# CM_PER register map
Vendor: Texas Instruments
Peripheral module from a debugger description file (folder am335x).
Registers are 32-bit, access per field, no defined reset value unless marked. A register's access mark holds for its fields unless they carry their own. Offsets are as the file gives them; lines under a group give offsets from that group; [hi:lo] are bit positions; {n}, {i} and the like mark numbered series; 'fields as' and 'values as' point back to an identical list; <NAME> marks a mode.

## CM_PER
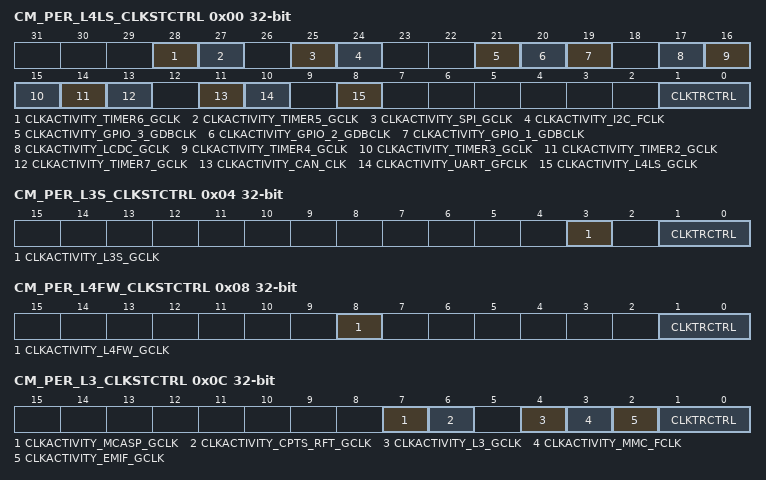
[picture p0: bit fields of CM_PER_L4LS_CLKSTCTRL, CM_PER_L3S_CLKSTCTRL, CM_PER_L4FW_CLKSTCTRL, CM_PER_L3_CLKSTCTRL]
0x00 CM_PER_L4LS_CLKSTCTRL — This register enables the domain power state transition. It controls the SW supervised clock domain state transition between ON-PER and ON-INPER states. It also hold one status bit per clock input of the domain.
  [28] CLKACTIVITY_TIMER6_GCLK ro — This field indicates the state of the TIMER6 CLKTIMER clock in the domain.
    0=Inact (Corresponding clock is gated); 1=Act (Corresponding clock is active)
  [27] CLKACTIVITY_TIMER5_GCLK ro — This field indicates the state of the TIMER5 CLKTIMER clock in the domain.
    values as CLKACTIVITY_TIMER6_GCLK
  [25] CLKACTIVITY_SPI_GCLK ro — This field indicates the state of the SPI_GCLK clock in the domain.
    values as CLKACTIVITY_TIMER6_GCLK
  [24] CLKACTIVITY_I2C_FCLK ro — This field indicates the state of the I2C _FCLK clock in the domain.
    values as CLKACTIVITY_TIMER6_GCLK
  [21] CLKACTIVITY_GPIO_3_GDBCLK ro — This field indicates the state of the GPIO3_GDBCLK clock in the domain.
    values as CLKACTIVITY_TIMER6_GCLK
  [20] CLKACTIVITY_GPIO_2_GDBCLK ro — This field indicates the state of the GPIO2_ GDBCLK clock in the domain.
    values as CLKACTIVITY_TIMER6_GCLK
  [19] CLKACTIVITY_GPIO_1_GDBCLK ro — This field indicates the state of the GPIO1_GDBCLK clock in the domain.
    values as CLKACTIVITY_TIMER6_GCLK
  [17] CLKACTIVITY_LCDC_GCLK ro — This field indicates the state of the LCD clock in the domain.
    values as CLKACTIVITY_TIMER6_GCLK
  [16] CLKACTIVITY_TIMER4_GCLK ro — This field indicates the state of the TIMER4 CLKTIMER clock in the domain.
    values as CLKACTIVITY_TIMER6_GCLK
  [15] CLKACTIVITY_TIMER3_GCLK ro — This field indicates the state of the TIMER3 CLKTIMER clock in the domain.
    values as CLKACTIVITY_TIMER6_GCLK
  [14] CLKACTIVITY_TIMER2_GCLK ro — This field indicates the state of the TIMER2 CLKTIMER clock in the domain.
    values as CLKACTIVITY_TIMER6_GCLK
  [13] CLKACTIVITY_TIMER7_GCLK ro — This field indicates the state of the TIMER7 CLKTIMER clock in the domain.
    values as CLKACTIVITY_TIMER6_GCLK
  [11] CLKACTIVITY_CAN_CLK ro — This field indicates the state of the CAN_CLK clock in the domain.
    values as CLKACTIVITY_TIMER6_GCLK
  [10] CLKACTIVITY_UART_GFCLK ro — This field indicates the state of the UART_GFCLK clock in the domain.
    values as CLKACTIVITY_TIMER6_GCLK
  [8] CLKACTIVITY_L4LS_GCLK ro — This field indicates the state of the L4LS_GCLK clock in the domain.
    values as CLKACTIVITY_TIMER6_GCLK
  [1:0] CLKTRCTRL rw — Controls the clock state transition of the L4 SLOW clock domain in PER power domain.
    0=NO_SLEEP (NO_SLEEP: Sleep transition cannot be initiated. Wakeup transition may however occur.); 1=SW_SLEEP (SW_SLEEP: Start a software forced sleep transition on the domain.); 2=SW_WKUP (SW_WKUP: Start a software forced wake-up transition on the domain.)
0x04 CM_PER_L3S_CLKSTCTRL — This register enables the domain power state transition. It controls the SW supervised clock domain state transition between ON-ACTIVE and ON-INACTIVE states. It also hold one status bit per clock input of the domain.
  [3] CLKACTIVITY_L3S_GCLK ro — This field indicates the state of the L3S_GCLK clock in the domain.
    0=Inact; 1=Act
  [1:0] CLKTRCTRL rw — Controls the clock state transition of the L3 Slow clock domain.
    values as CM_PER_L4LS_CLKSTCTRL.CLKTRCTRL
0x08 CM_PER_L4FW_CLKSTCTRL — This register enables the domain power state transition. It controls the SW supervised clock domain state transition between ON-ACTIVE and ON-INACTIVE states. It also hold one status bit per clock input of the domain.
  [8] CLKACTIVITY_L4FW_GCLK ro — This field indicates the state of the L4FW clock in the domain.
    values as CM_PER_L4LS_CLKSTCTRL.CLKACTIVITY_TIMER6_GCLK
  [1:0] CLKTRCTRL rw — Controls the clock state transition of the L4 Firewall clock domain.
    values as CM_PER_L4LS_CLKSTCTRL.CLKTRCTRL
0x0C CM_PER_L3_CLKSTCTRL — This register enables the domain power state transition. It controls the SW supervised clock domain state transition between ON-ACTIVE and ON-INACTIVE states. It also hold one status bit per clock input of the domain.
  [7] CLKACTIVITY_MCASP_GCLK ro — This field indicates the state of the MCASP_GCLK clock in the domain.
    0=Inact; 1=Act
  [6] CLKACTIVITY_CPTS_RFT_GCLK ro — This field indicates the state of the CLKACTIVITY_CPTS_RFT_GCLK clock in the domain.
    0=Inact; 1=Act
  [4] CLKACTIVITY_L3_GCLK ro — This field indicates the state of the L3_GCLK clock in the domain.
    0=Inact; 1=Act
  [3] CLKACTIVITY_MMC_FCLK ro — This field indicates the state of the MMC_GCLK clock in the domain.
    0=Inact; 1=Act
  [2] CLKACTIVITY_EMIF_GCLK ro — This field indicates the state of the EMIF_GCLK clock in the domain.
    0=Inact; 1=Act
  [1:0] CLKTRCTRL rw — Controls the clock state transition of the L3 clock domain.
    values as CM_PER_L4LS_CLKSTCTRL.CLKTRCTRL
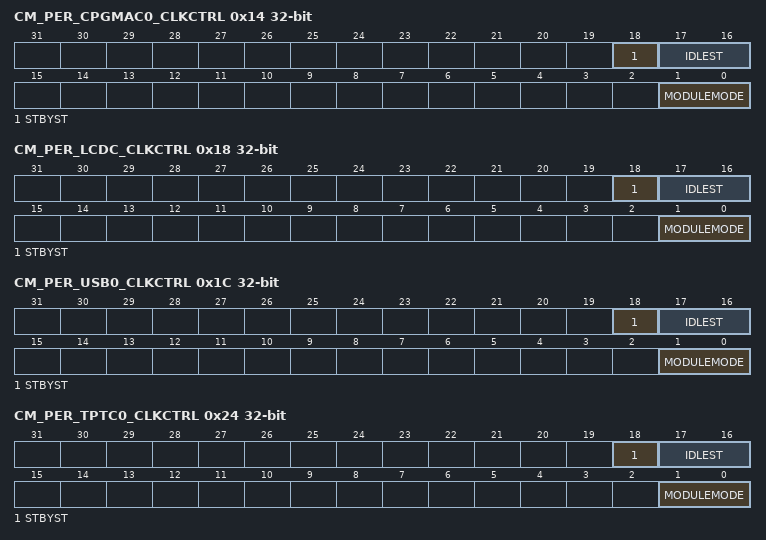
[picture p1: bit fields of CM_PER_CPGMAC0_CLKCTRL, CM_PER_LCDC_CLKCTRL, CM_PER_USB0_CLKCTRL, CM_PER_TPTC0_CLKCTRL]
0x14 CM_PER_CPGMAC0_CLKCTRL — This register manages the CPSW clocks.
  [18] STBYST ro — Module standby status. This bit is warm reset insensitive when CPSW RESET_ISO is enabled
    0=Func (Module is functional (not in standby)); 1=Standby (Module is in standby)
  [17:16] IDLEST ro — Module idle status. This bit is warm reset insensitive when CPSW RESET_ISO is enabled
    0=Func (Module is fully functional, including OCP); 1=Trans (Module is performing transition: wakeup, or sleep, or sleep abortion); 2=Idle (Module is in Idle mode (only OCP part). It is functional if using separate functional clock); 3=Disable (Module is disabled and cannot be accessed)
  [1:0] MODULEMODE rw — Control the way mandatory clocks are managed. This bit is warm reset insensitive when CPSW RESET_ISO is enabled
    0=DISABLED (Module is disable by SW. Any OCP access to module results in an error, except if resulting from a module wakeup (asynchronous wakeup).); 2=ENABLE (Module is explicitly enabled. Interface clock (if not used for functions) may be gated according to the clock domain state. Functional clocks are guarantied to stay present. As long as in this configuration, power domain sleep transition cannot happen.)
0x18 CM_PER_LCDC_CLKCTRL — This register manages the LCD clocks.
  [18] STBYST ro — Module standby status.
    values as CM_PER_CPGMAC0_CLKCTRL.STBYST
  [17:16] IDLEST ro — Module idle status.
    values as CM_PER_CPGMAC0_CLKCTRL.IDLEST
  [1:0] MODULEMODE rw — Control the way mandatory clocks are managed.
    values as CM_PER_CPGMAC0_CLKCTRL.MODULEMODE
0x1C CM_PER_USB0_CLKCTRL — This register manages the USB clocks.
  fields as CM_PER_LCDC_CLKCTRL
0x24 CM_PER_TPTC0_CLKCTRL — This register manages the TPTC clocks.
  fields as CM_PER_LCDC_CLKCTRL
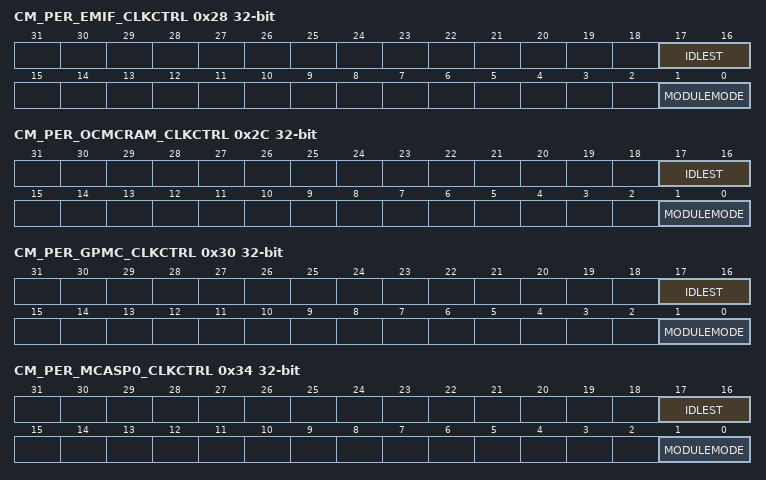
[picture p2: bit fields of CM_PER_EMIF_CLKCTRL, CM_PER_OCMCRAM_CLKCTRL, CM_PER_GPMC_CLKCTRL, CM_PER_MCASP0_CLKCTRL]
0x28 CM_PER_EMIF_CLKCTRL — This register manages the EMIF clocks.
  [17:16] IDLEST ro — Module idle status.
    values as CM_PER_CPGMAC0_CLKCTRL.IDLEST
  [1:0] MODULEMODE rw — Control the way mandatory clocks are managed.
    values as CM_PER_CPGMAC0_CLKCTRL.MODULEMODE
0x2C CM_PER_OCMCRAM_CLKCTRL — This register manages the OCMC clocks.
  fields as CM_PER_EMIF_CLKCTRL
0x30 CM_PER_GPMC_CLKCTRL — This register manages the GPMC clocks.
  fields as CM_PER_EMIF_CLKCTRL
0x34 CM_PER_MCASP0_CLKCTRL — This register manages the MCASP0 clocks.
  fields as CM_PER_EMIF_CLKCTRL
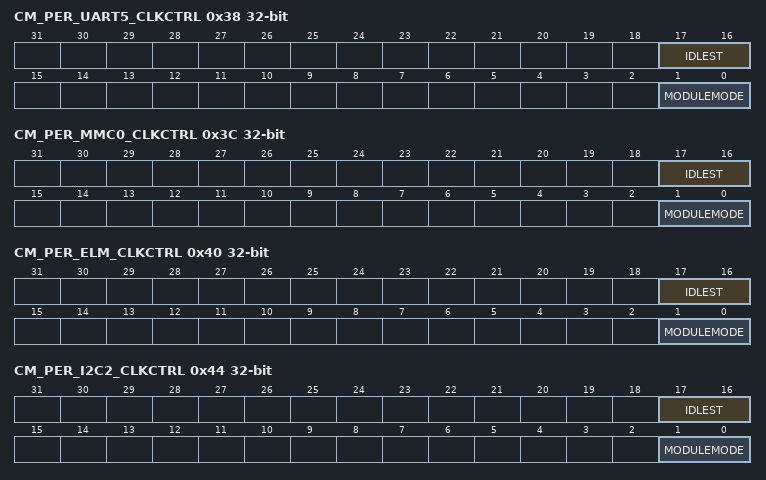
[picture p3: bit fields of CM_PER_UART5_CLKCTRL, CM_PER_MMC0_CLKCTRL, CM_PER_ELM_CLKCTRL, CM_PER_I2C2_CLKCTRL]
0x38 CM_PER_UART5_CLKCTRL — This register manages the UART5 clocks.
  fields as CM_PER_EMIF_CLKCTRL
0x3C CM_PER_MMC0_CLKCTRL — This register manages the MMC0 clocks.
  fields as CM_PER_EMIF_CLKCTRL
0x40 CM_PER_ELM_CLKCTRL — This register manages the ELM clocks.
  fields as CM_PER_EMIF_CLKCTRL
0x44 CM_PER_I2C2_CLKCTRL — This register manages the I2C2 clocks.
  fields as CM_PER_EMIF_CLKCTRL
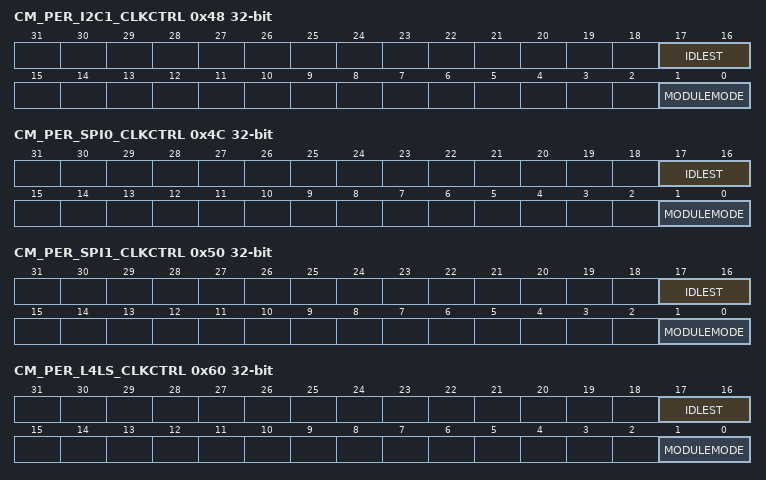
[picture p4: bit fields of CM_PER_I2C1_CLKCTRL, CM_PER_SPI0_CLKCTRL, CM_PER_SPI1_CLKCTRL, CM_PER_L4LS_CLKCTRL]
0x48 CM_PER_I2C1_CLKCTRL — This register manages the I2C1 clocks.
  fields as CM_PER_EMIF_CLKCTRL
0x4C CM_PER_SPI0_CLKCTRL — This register manages the SPI0 clocks.
  fields as CM_PER_EMIF_CLKCTRL
0x50 CM_PER_SPI1_CLKCTRL — This register manages the SPI1 clocks.
  fields as CM_PER_EMIF_CLKCTRL
0x60 CM_PER_L4LS_CLKCTRL — This register manages the L4LS clocks.
  fields as CM_PER_EMIF_CLKCTRL
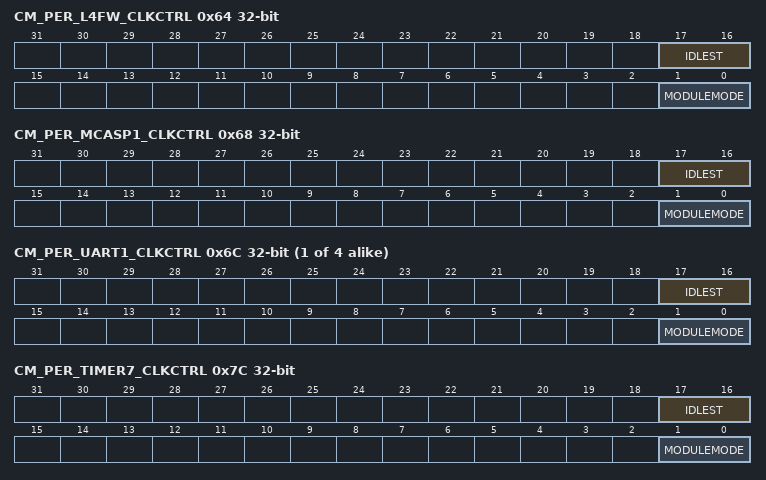
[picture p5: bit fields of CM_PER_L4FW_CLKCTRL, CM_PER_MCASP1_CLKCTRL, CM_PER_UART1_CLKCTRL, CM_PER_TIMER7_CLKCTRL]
0x64 CM_PER_L4FW_CLKCTRL — This register manages the L4FW clocks.
  fields as CM_PER_EMIF_CLKCTRL
0x68 CM_PER_MCASP1_CLKCTRL — This register manages the MCASP1 clocks.
  fields as CM_PER_EMIF_CLKCTRL
{0x68+4i} CM_PER_UART{i}_CLKCTRL (i=1..4) — This register manages the UART{i} clocks.
  fields as CM_PER_EMIF_CLKCTRL
0x7C CM_PER_TIMER7_CLKCTRL — This register manages the TIMER7 clocks.
  fields as CM_PER_EMIF_CLKCTRL
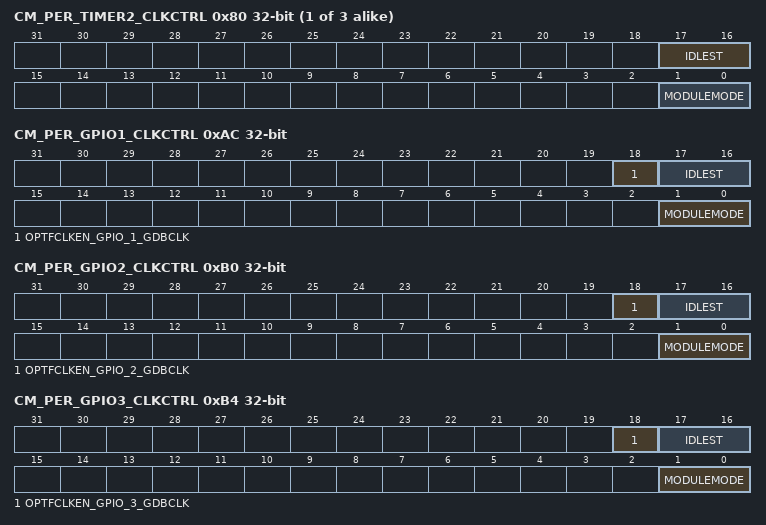
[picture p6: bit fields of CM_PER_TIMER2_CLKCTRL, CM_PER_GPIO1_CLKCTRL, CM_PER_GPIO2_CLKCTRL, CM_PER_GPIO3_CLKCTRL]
{0x78+4i} CM_PER_TIMER{i}_CLKCTRL (i=2..4) — This register manages the TIMER{i} clocks.
  fields as CM_PER_EMIF_CLKCTRL
0xAC CM_PER_GPIO1_CLKCTRL — This register manages the GPIO1 clocks.
  [18] OPTFCLKEN_GPIO_1_GDBCLK rw — Optional functional clock control.
    0=FCLK_DIS (Optional functional clock is disabled); 1=FCLK_EN (Optional functional clock is enabled)
  [17:16] IDLEST ro — Module idle status.
    values as CM_PER_CPGMAC0_CLKCTRL.IDLEST
  [1:0] MODULEMODE rw — Control the way mandatory clocks are managed.
    0=DISABLED (Module is disable by SW. Any OCP access to module results in an error, except if resulting from a module wakeup (asynchronous wakeup).); 2=ENABLE (Module is explicitly enabled. Interface clock (if not used for functions) may be gated according to the clock domain state. Functional clocks are guaranteed to stay present. As long as in this configuration, power domain sleep transition cannot happen.)
0xB0 CM_PER_GPIO2_CLKCTRL — This register manages the GPIO2 clocks.
  [18] OPTFCLKEN_GPIO_2_GDBCLK rw — Optional functional clock control.
    values as CM_PER_GPIO1_CLKCTRL.OPTFCLKEN_GPIO_1_GDBCLK
  [17:16] IDLEST ro — Module idle status.
    values as CM_PER_CPGMAC0_CLKCTRL.IDLEST
  [1:0] MODULEMODE rw — Control the way mandatory clocks are managed.
    values as CM_PER_CPGMAC0_CLKCTRL.MODULEMODE
0xB4 CM_PER_GPIO3_CLKCTRL — This register manages the GPIO3 clocks.
  [18] OPTFCLKEN_GPIO_3_GDBCLK rw — Optional functional clock control.
    values as CM_PER_GPIO1_CLKCTRL.OPTFCLKEN_GPIO_1_GDBCLK
  [17:16] IDLEST ro — Module idle status.
    values as CM_PER_CPGMAC0_CLKCTRL.IDLEST
  [1:0] MODULEMODE rw — Control the way mandatory clocks are managed.
    values as CM_PER_CPGMAC0_CLKCTRL.MODULEMODE
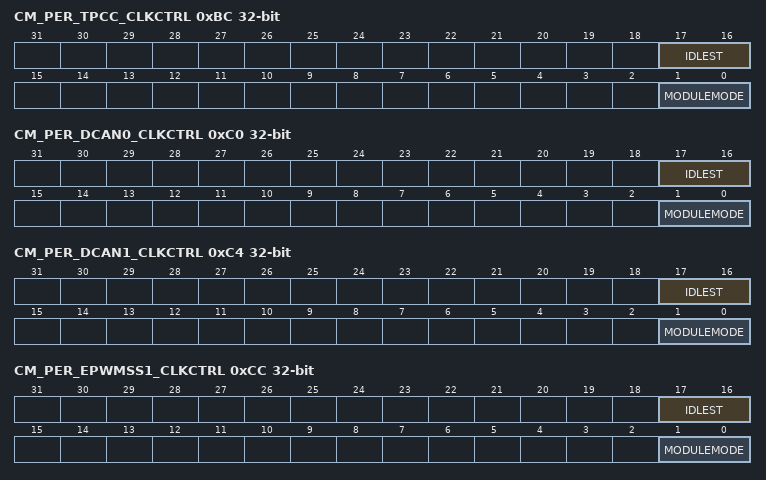
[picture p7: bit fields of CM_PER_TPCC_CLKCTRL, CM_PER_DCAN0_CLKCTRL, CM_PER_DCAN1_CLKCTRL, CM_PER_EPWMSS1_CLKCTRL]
0xBC CM_PER_TPCC_CLKCTRL — This register manages the TPCC clocks.
  fields as CM_PER_EMIF_CLKCTRL
0xC0 CM_PER_DCAN0_CLKCTRL — This register manages the DCAN0 clocks.
  fields as CM_PER_EMIF_CLKCTRL
0xC4 CM_PER_DCAN1_CLKCTRL — This register manages the DCAN1 clocks.
  fields as CM_PER_EMIF_CLKCTRL
0xCC CM_PER_EPWMSS1_CLKCTRL — This register manages the PWMSS1 clocks.
  fields as CM_PER_EMIF_CLKCTRL
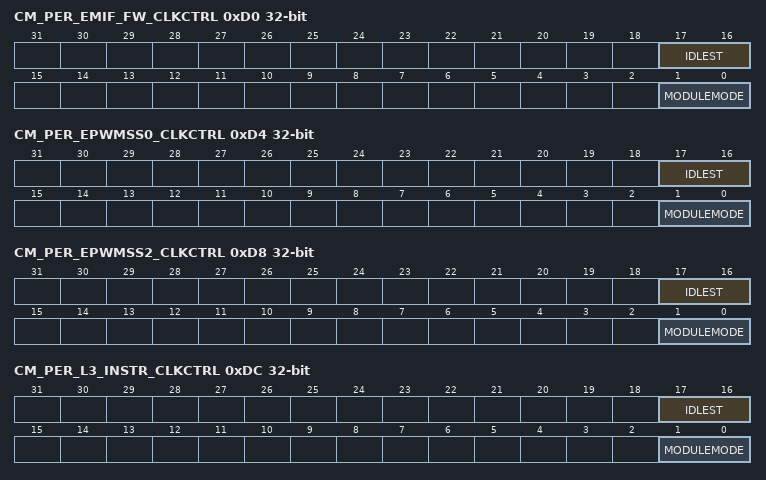
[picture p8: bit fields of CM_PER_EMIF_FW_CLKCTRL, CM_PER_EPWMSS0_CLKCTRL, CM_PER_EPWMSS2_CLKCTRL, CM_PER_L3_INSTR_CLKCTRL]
0xD0 CM_PER_EMIF_FW_CLKCTRL — This register manages the EMIF Firewall clocks.
  fields as CM_PER_EMIF_CLKCTRL
0xD4 CM_PER_EPWMSS0_CLKCTRL — This register manages the PWMSS0 clocks.
  fields as CM_PER_EMIF_CLKCTRL
0xD8 CM_PER_EPWMSS2_CLKCTRL — This register manages the PWMSS2 clocks.
  fields as CM_PER_EMIF_CLKCTRL
0xDC CM_PER_L3_INSTR_CLKCTRL — This register manages the L3 INSTR clocks.
  fields as CM_PER_EMIF_CLKCTRL
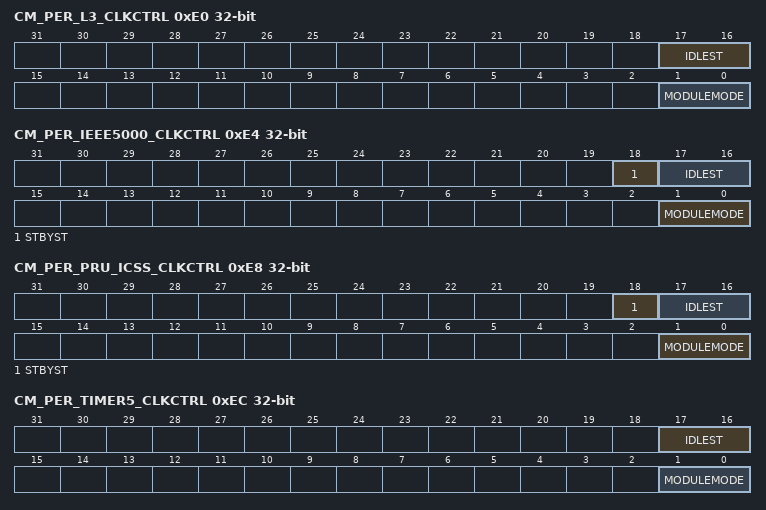
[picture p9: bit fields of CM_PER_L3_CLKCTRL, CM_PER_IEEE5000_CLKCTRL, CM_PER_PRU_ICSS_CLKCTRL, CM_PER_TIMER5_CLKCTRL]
0xE0 CM_PER_L3_CLKCTRL — This register manages the L3 Interconnect clocks.
  fields as CM_PER_EMIF_CLKCTRL
0xE4 CM_PER_IEEE5000_CLKCTRL — This register manages the IEEE1500 clocks.
  fields as CM_PER_LCDC_CLKCTRL
0xE8 CM_PER_PRU_ICSS_CLKCTRL — This register manages the PRU-ICSS clocks.
  fields as CM_PER_LCDC_CLKCTRL
0xEC CM_PER_TIMER5_CLKCTRL — This register manages the TIMER5 clocks.
  fields as CM_PER_EMIF_CLKCTRL
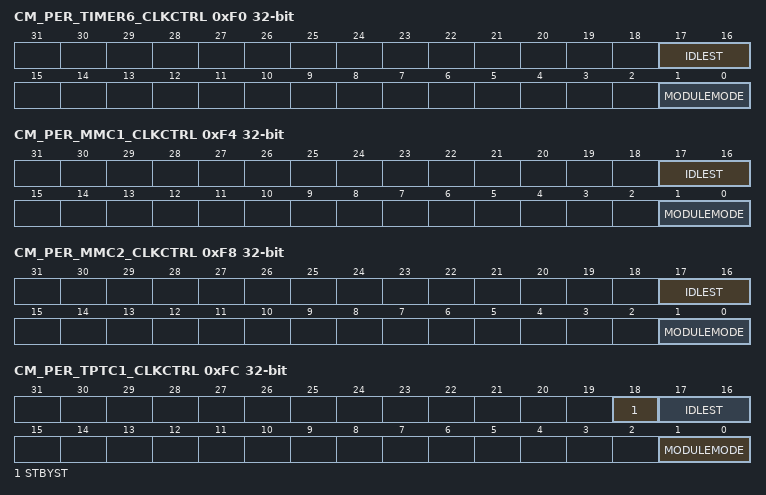
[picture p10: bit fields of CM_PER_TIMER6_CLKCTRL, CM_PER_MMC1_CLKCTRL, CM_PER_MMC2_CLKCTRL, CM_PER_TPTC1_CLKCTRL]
0xF0 CM_PER_TIMER6_CLKCTRL — This register manages the TIMER6 clocks.
  fields as CM_PER_EMIF_CLKCTRL
0xF4 CM_PER_MMC1_CLKCTRL — This register manages the MMC1 clocks.
  fields as CM_PER_EMIF_CLKCTRL
0xF8 CM_PER_MMC2_CLKCTRL — This register manages the MMC2 clocks.
  fields as CM_PER_EMIF_CLKCTRL
0xFC CM_PER_TPTC1_CLKCTRL — This register manages the TPTC1 clocks.
  fields as CM_PER_LCDC_CLKCTRL
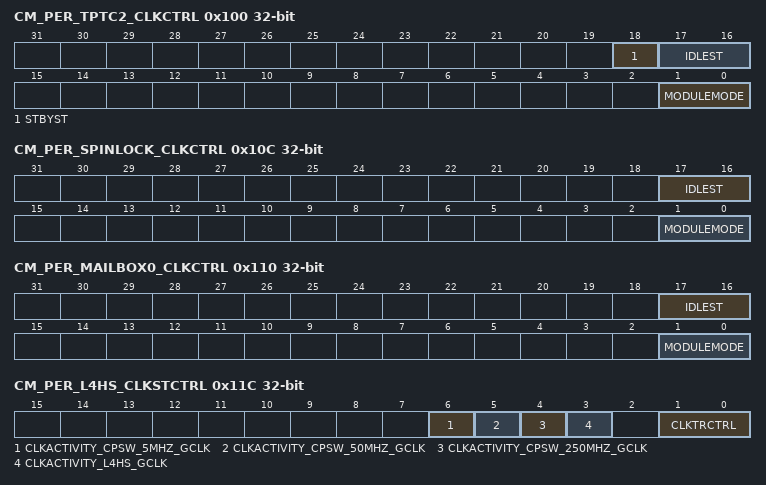
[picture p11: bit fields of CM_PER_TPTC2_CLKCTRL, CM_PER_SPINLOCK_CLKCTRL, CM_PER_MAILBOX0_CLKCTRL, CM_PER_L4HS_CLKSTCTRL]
0x100 CM_PER_TPTC2_CLKCTRL — This register manages the TPTC2 clocks.
  fields as CM_PER_LCDC_CLKCTRL
0x10C CM_PER_SPINLOCK_CLKCTRL — This register manages the SPINLOCK clocks.
  fields as CM_PER_EMIF_CLKCTRL
0x110 CM_PER_MAILBOX0_CLKCTRL — This register manages the MAILBOX0 clocks.
  fields as CM_PER_EMIF_CLKCTRL
0x11C CM_PER_L4HS_CLKSTCTRL — This register enables the domain power state transition. It controls the SW supervised clock domain state transition between ON-ACTIVE and ON-INACTIVE states. It also hold one status bit per clock input of the domain.
  [6] CLKACTIVITY_CPSW_5MHZ_GCLK ro — This field indicates the state of the CPSW_5MHZ_GCLK clock in the domain.
    0=Inact; 1=Act
  [5] CLKACTIVITY_CPSW_50MHZ_GCLK ro — This field indicates the state of the CPSW_50MHZ_GCLK clock in the domain.
    0=Inact; 1=Act
  [4] CLKACTIVITY_CPSW_250MHZ_GCLK ro — This field indicates the state of the CPSW_250MHZ_GCLK clock in the domain.
    0=Inact; 1=Act
  [3] CLKACTIVITY_L4HS_GCLK ro — This field indicates the state of the L4HS_GCLK clock in the domain.
    0=Inact; 1=Act
  [1:0] CLKTRCTRL rw — Controls the clock state transition of the L4 Fast clock domain.
    values as CM_PER_L4LS_CLKSTCTRL.CLKTRCTRL
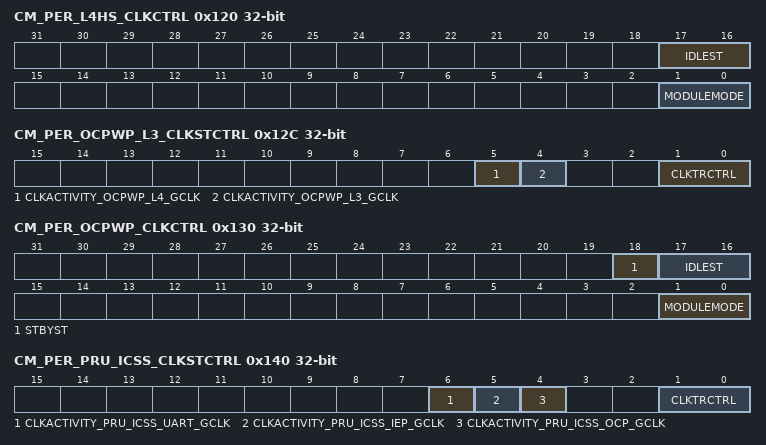
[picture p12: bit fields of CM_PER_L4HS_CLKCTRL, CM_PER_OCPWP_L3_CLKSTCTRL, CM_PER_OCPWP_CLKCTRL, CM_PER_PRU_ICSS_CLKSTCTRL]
0x120 CM_PER_L4HS_CLKCTRL — This register manages the L4 Fast clocks.
  fields as CM_PER_EMIF_CLKCTRL
0x12C CM_PER_OCPWP_L3_CLKSTCTRL — This register enables the domain power state transition. It controls the SW supervised clock domain state transition between ON-ACTIVE and ON-INACTIVE states. It also hold one status bit per clock input of the domain.
  [5] CLKACTIVITY_OCPWP_L4_GCLK ro — This field indicates the state of the OCPWP L4 clock in the domain.
    0=Inact; 1=Act
  [4] CLKACTIVITY_OCPWP_L3_GCLK ro — This field indicates the state of the OCPWP L3 clock in the domain.
    0=Inact; 1=Act
  [1:0] CLKTRCTRL rw — Controls the clock state transition of the OCPWP clock domain.
    values as CM_PER_L4LS_CLKSTCTRL.CLKTRCTRL
0x130 CM_PER_OCPWP_CLKCTRL — This register manages the OCPWP clocks.
  fields as CM_PER_LCDC_CLKCTRL
0x140 CM_PER_PRU_ICSS_CLKSTCTRL — This register enables the clock domain state transition. It controls the SW supervised clock domain state transition between ON-ACTIVE and ON-INACTIVE states. It also hold one status bit per clock input of the domain.
  [6] CLKACTIVITY_PRU_ICSS_UART_GCLK ro — This field indicates the state of the PRU-ICSS UART clock in the domain.
    0=Inact; 1=Act
  [5] CLKACTIVITY_PRU_ICSS_IEP_GCLK ro — This field indicates the state of the PRU-ICSS IEP clock in the domain.
    0=Inact; 1=Act
  [4] CLKACTIVITY_PRU_ICSS_OCP_GCLK ro — This field indicates the state of the PRU-ICSS OCP clock in the domain.
    0=Inact; 1=Act
  [1:0] CLKTRCTRL rw — Controls the clock state transition of the PRU-ICSS OCP clock domain.
    values as CM_PER_L4LS_CLKSTCTRL.CLKTRCTRL
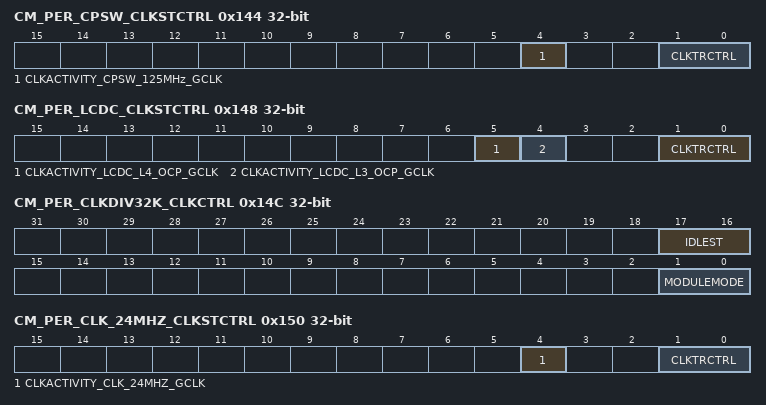
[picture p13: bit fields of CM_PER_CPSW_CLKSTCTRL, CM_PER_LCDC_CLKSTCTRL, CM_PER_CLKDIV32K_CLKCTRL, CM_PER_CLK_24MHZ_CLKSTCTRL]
0x144 CM_PER_CPSW_CLKSTCTRL — This register enables the clock domain state transition. It controls the SW supervised clock domain state transition between ON-ACTIVE and ON-INACTIVE states. It also hold one status bit per clock input of the domain.
  [4] CLKACTIVITY_CPSW_125MHz_GCLK ro — This field indicates the state of the CPSW 125 MHz OCP clock in the domain.
    0=Inact; 1=Act
  [1:0] CLKTRCTRL rw — Controls the clock state transition of the CPSW OCP clock domain.
    values as CM_PER_L4LS_CLKSTCTRL.CLKTRCTRL
0x148 CM_PER_LCDC_CLKSTCTRL — This register enables the clock domain state transition. It controls the SW supervised clock domain state transition between ON-ACTIVE and ON-INACTIVE states. It also hold one status bit per clock input of the domain.
  [5] CLKACTIVITY_LCDC_L4_OCP_GCLK ro — This field indicates the state of the LCDC L4 OCP clock in the domain.
    0=Inact; 1=Act
  [4] CLKACTIVITY_LCDC_L3_OCP_GCLK ro — This field indicates the state of the LCDC L3 OCP clock in the domain.
    0=Inact; 1=Act
  [1:0] CLKTRCTRL rw — Controls the clock state transition of the LCDC OCP clock domain.
    values as CM_PER_L4LS_CLKSTCTRL.CLKTRCTRL
0x14C CM_PER_CLKDIV32K_CLKCTRL — This register manages the CLKDIV32K clocks.
  fields as CM_PER_EMIF_CLKCTRL
0x150 CM_PER_CLK_24MHZ_CLKSTCTRL — This register enables the clock domain state transition. It controls the SW supervised clock domain state transition between ON-ACTIVE and ON-INACTIVE states. It also hold one status bit per clock input of the domain.
  [4] CLKACTIVITY_CLK_24MHZ_GCLK ro — This field indicates the state of the 24MHz clock in the domain.
    0=Inact; 1=Act
  [1:0] CLKTRCTRL rw — Controls the clock state transition of the 24MHz clock domain.
    values as CM_PER_L4LS_CLKSTCTRL.CLKTRCTRL
